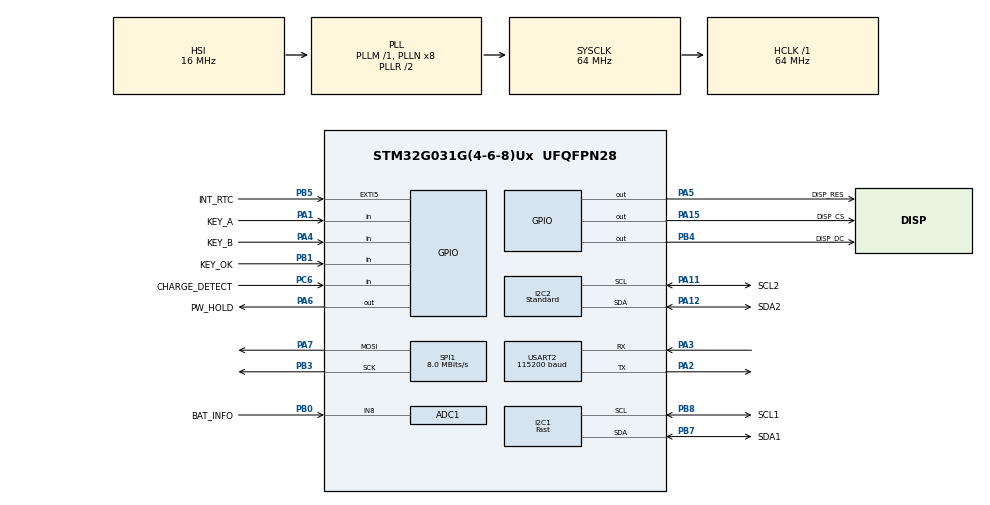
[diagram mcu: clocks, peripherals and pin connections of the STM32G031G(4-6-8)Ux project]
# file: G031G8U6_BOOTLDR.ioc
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ADC1.Channel-1\#ChannelRegularConversion=ADC_CHANNEL_8
ADC1.ClockPrescaler=ADC_CLOCK_SYNC_PCLK_DIV2
ADC1.ContinuousConvMode=ENABLE
ADC1.DMAContinuousRequests=ENABLE
ADC1.EOCSelection=ADC_EOC_SEQ_CONV
ADC1.NbrOfConversion=1
ADC1.NbrOfConversionFlag=1
ADC1.Overrun=ADC_OVR_DATA_PRESERVED
ADC1.OversamplingMode=ENABLE
ADC1.Rank-1\#ChannelRegularConversion=1
ADC1.Ratio=ADC_OVERSAMPLING_RATIO_256
ADC1.Resolution=ADC_RESOLUTION_12B
ADC1.RightBitShift=ADC_RIGHTBITSHIFT_4
ADC1.SamplingTime-1\#ChannelRegularConversion=ADC_SAMPLINGTIME_COMMON_1
ADC1.SamplingTimeCommon1=ADC_SAMPLETIME_39CYCLES_5
ADC1.SamplingTimeCommon2=ADC_SAMPLETIME_39CYCLES_5
ADC1.SelectedChannel=ADC_CHANNEL_8
ADC1.TriggerFrequencyMode=ADC_TRIGGER_FREQ_LOW
ADC1.master=1
Dma.ADC1.2.Direction=DMA_PERIPH_TO_MEMORY
Dma.ADC1.2.EventEnable=DISABLE
Dma.ADC1.2.Instance=DMA1_Channel3
Dma.ADC1.2.MemDataAlignment=DMA_MDATAALIGN_HALFWORD
Dma.ADC1.2.MemInc=DMA_MINC_ENABLE
Dma.ADC1.2.Mode=DMA_CIRCULAR
Dma.ADC1.2.PeriphDataAlignment=DMA_PDATAALIGN_HALFWORD
Dma.ADC1.2.PeriphInc=DMA_PINC_DISABLE
Dma.ADC1.2.Polarity=HAL_DMAMUX_REQ_GEN_RISING
Dma.ADC1.2.Priority=DMA_PRIORITY_VERY_HIGH
Dma.ADC1.2.RequestNumber=1
Dma.ADC1.2.SignalID=NONE
Dma.ADC1.2.SyncEnable=DISABLE
Dma.ADC1.2.SyncPolarity=HAL_DMAMUX_SYNC_NO_EVENT
Dma.ADC1.2.SyncRequestNumber=1
Dma.ADC1.2.SyncSignalID=NONE
Dma.Request0=USART2_RX
Dma.Request1=USART2_TX
Dma.Request2=ADC1
Dma.USART2_RX.0.Direction=DMA_PERIPH_TO_MEMORY
Dma.USART2_RX.0.EventEnable=DISABLE
Dma.USART2_RX.0.Instance=DMA1_Channel1
Dma.USART2_RX.0.MemDataAlignment=DMA_MDATAALIGN_BYTE
Dma.USART2_RX.0.MemInc=DMA_MINC_ENABLE
Dma.USART2_RX.0.Mode=DMA_NORMAL
Dma.USART2_RX.0.PeriphDataAlignment=DMA_PDATAALIGN_BYTE
Dma.USART2_RX.0.PeriphInc=DMA_PINC_DISABLE
Dma.USART2_RX.0.Polarity=HAL_DMAMUX_REQ_GEN_RISING
Dma.USART2_RX.0.Priority=DMA_PRIORITY_LOW
Dma.USART2_RX.0.RequestNumber=1
Dma.USART2_RX.0.SignalID=NONE
Dma.USART2_RX.0.SyncEnable=DISABLE
Dma.USART2_RX.0.SyncPolarity=HAL_DMAMUX_SYNC_NO_EVENT
Dma.USART2_RX.0.SyncRequestNumber=1
Dma.USART2_RX.0.SyncSignalID=NONE
Dma.USART2_TX.1.Direction=DMA_MEMORY_TO_PERIPH
Dma.USART2_TX.1.EventEnable=DISABLE
Dma.USART2_TX.1.Instance=DMA1_Channel2
Dma.USART2_TX.1.MemDataAlignment=DMA_MDATAALIGN_BYTE
Dma.USART2_TX.1.MemInc=DMA_MINC_ENABLE
Dma.USART2_TX.1.Mode=DMA_NORMAL
Dma.USART2_TX.1.PeriphDataAlignment=DMA_PDATAALIGN_BYTE
Dma.USART2_TX.1.PeriphInc=DMA_PINC_DISABLE
Dma.USART2_TX.1.Polarity=HAL_DMAMUX_REQ_GEN_RISING
Dma.USART2_TX.1.Priority=DMA_PRIORITY_LOW
Dma.USART2_TX.1.RequestNumber=1
Dma.USART2_TX.1.SignalID=NONE
Dma.USART2_TX.1.SyncEnable=DISABLE
Dma.USART2_TX.1.SyncPolarity=HAL_DMAMUX_SYNC_NO_EVENT
Dma.USART2_TX.1.SyncRequestNumber=1
Dma.USART2_TX.1.SyncSignalID=NONE
I2C1.I2C_Speed_Mode=I2C_Fast
I2C1.Timing=0x00602173
I2C2.I2C_Speed_Mode=I2C_Standard
I2C2.Timing=0x10707DBC
Mcu.Family=STM32G0
Mcu.Name=STM32G031G(4-6-8)Ux
Mcu.Package=UFQFPN28
NVIC.ADC1_IRQn=true\:0\:0\:true\:false\:true\:true\:true
NVIC.DMA1_Channel1_IRQn=true\:3\:0\:true\:false\:true\:false\:true
NVIC.DMA1_Channel2_3_IRQn=true\:3\:0\:true\:false\:true\:false\:true
NVIC.EXTI4_15_IRQn=true\:2\:0\:true\:false\:true\:true\:true
NVIC.TIM17_IRQn=true\:3\:0\:true\:false\:true\:false\:true
NVIC.TimeBase=TIM17_IRQn
NVIC.TimeBaseIP=TIM17
NVIC.USART2_IRQn=true\:0\:0\:false\:false\:true\:true\:true
PA1.GPIO_Label=KEY_A
PA1.GPIO_PuPd=GPIO_PULLUP
PA1.Signal=GPIO_Input
PA11\ [PA9].GPIO_Label=SCL2
PA11\ [PA9].Mode=I2C
PA11\ [PA9].Signal=I2C2_SCL
PA12\ [PA10].GPIO_Label=SDA2
PA12\ [PA10].Mode=I2C
PA12\ [PA10].Signal=I2C2_SDA
PA13.Mode=Serial_Wire
PA13.Signal=SYS_SWDIO
PA14-BOOT0.Mode=Serial_Wire
PA14-BOOT0.Signal=SYS_SWCLK
PA15.GPIO_Label=DISP_CS
PA15.Signal=GPIO_Output
PA2.Mode=Asynchronous
PA2.Signal=USART2_TX
PA3.Mode=Asynchronous
PA3.Signal=USART2_RX
PA4.GPIO_Label=KEY_B
PA4.GPIO_PuPd=GPIO_PULLUP
PA4.Signal=GPIO_Input
PA5.GPIO_Label=DISP_RES
PA5.Signal=GPIO_Output
PA6.GPIO_Label=PW_HOLD
PA6.Signal=GPIO_Output
PA7.Mode=TX_Only_Simplex_Unidirect_Master
PA7.Signal=SPI1_MOSI
PB0.GPIO_Label=BAT_INFO
PB0.Mode=IN8
PB0.Signal=ADC1_IN8
PB1.GPIO_Label=KEY_OK
PB1.GPIO_PuPd=GPIO_PULLUP
PB1.Signal=GPIO_Input
PB3.Mode=TX_Only_Simplex_Unidirect_Master
PB3.Signal=SPI1_SCK
PB4.GPIO_Label=DISP_DC
PB4.Signal=GPIO_Output
PB5.GPIO_Label=INT_RTC
PB5.GPIO_ModeDefaultEXTI=GPIO_MODE_IT_FALLING
PB5.GPIO_PuPd=GPIO_PULLUP
PB5.Signal=GPXTI5
PB7.GPIO_Label=SDA1
PB7.Mode=I2C
PB7.Signal=I2C1_SDA
PB8.GPIO_Label=SCL1
PB8.Mode=I2C
PB8.Signal=I2C1_SCL
PC6.GPIO_Label=CHARGE_DETECT
PC6.Signal=GPIO_Input
ProjectManager.HeapSize=0x400
ProjectManager.StackSize=0x400
ProjectManager.TargetToolchain=STM32CubeIDE
RCC.ADCFreq_Value=64000000
RCC.AHBFreq_Value=64000000
RCC.CortexFreq_Value=64000000
RCC.EXTERNAL_CLOCK_VALUE=12288000
RCC.HCLKFreq_Value=64000000
RCC.HSE_VALUE=8000000
RCC.HSI_VALUE=16000000
RCC.LSE_VALUE=32768
RCC.SYSCLKFreq_VALUE=64000000
RCC.SYSCLKSource=RCC_SYSCLKSOURCE_PLLCLK
RCC.VCOOutputFreq_Value=128000000
SPI1.BaudRatePrescaler=SPI_BAUDRATEPRESCALER_8
SPI1.CalculateBaudRate=8.0 MBits/s
SPI1.Direction=SPI_DIRECTION_2LINES
SPI1.Mode=SPI_MODE_MASTER
SPI1.VirtualType=VM_MASTER
USART2.BaudRate=115200
USART2.VirtualMode-Asynchronous=VM_ASYNC
VP_SYS_VS_tim17.Mode=TIM17
board=custom

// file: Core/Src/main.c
/* USER CODE BEGIN Header */
/**
  ******************************************************************************
  * @file           : main.c
  * @brief          : Main program body
  ******************************************************************************
  * @attention
  *
  * <h2><center>&copy; Copyright (c) 2022 STMicroelectronics.
  * All rights reserved.</center></h2>
  *
  * This software component is licensed by ST under BSD 3-Clause license,
  * the "License"; You may not use this file except in compliance with the
  * License. You may obtain a copy of the License at:
  *                        opensource.org/licenses/BSD-3-Clause
  *
  ******************************************************************************
  */
/* USER CODE END Header */
#include "main.h"

/* USER CODE BEGIN Includes */
#include <stdio.h>	//提供c库函数printf重定向到USARTx
#include <string.h>
#include <stdarg.h>
#include "BSP.h"
#include "cppports.h"
/* USER CODE END Includes */

ADC_HandleTypeDef hadc1;
DMA_HandleTypeDef hdma_adc1;

I2C_HandleTypeDef hi2c1;
I2C_HandleTypeDef hi2c2;

SPI_HandleTypeDef hspi1;

UART_HandleTypeDef huart2;
DMA_HandleTypeDef hdma_usart2_rx;
DMA_HandleTypeDef hdma_usart2_tx;

void SystemClock_Config(void);
static void MX_GPIO_Init(void);
static void MX_USART2_UART_Init(void);
static void MX_DMA_Init(void);
static void MX_SPI1_Init(void);
static void MX_I2C2_Init(void);
static void MX_I2C1_Init(void);
static void MX_ADC1_Init(void);

int main(void)
{

  /* MCU Configuration--------------------------------------------------------*/

  /* Reset of all peripherals, Initializes the Flash interface and the Systick. */
  HAL_Init();

  /* Configure the system clock */
  SystemClock_Config();

  /* Initialize all configured peripherals */
  MX_GPIO_Init();
  MX_USART2_UART_Init();
  MX_DMA_Init();
  MX_SPI1_Init();
  MX_I2C2_Init();
  MX_I2C1_Init();
  MX_ADC1_Init();
  /* USER CODE BEGIN 2 */
  FRToI2CxSInit();//解锁I2C

  setup();
  /* USER CODE END 2 */

  /* Infinite loop */
  while (1)
  {

  }
}

void SystemClock_Config(void)
{
  RCC_OscInitTypeDef RCC_OscInitStruct = {0};
  RCC_ClkInitTypeDef RCC_ClkInitStruct = {0};
  RCC_PeriphCLKInitTypeDef PeriphClkInit = {0};

  /** Configure the main internal regulator output voltage
  */
  HAL_PWREx_ControlVoltageScaling(PWR_REGULATOR_VOLTAGE_SCALE1);
  /** Initializes the RCC Oscillators according to the specified parameters
  * in the RCC_OscInitTypeDef structure.
  */
  RCC_OscInitStruct.OscillatorType = RCC_OSCILLATORTYPE_HSI;
  RCC_OscInitStruct.HSIState = RCC_HSI_ON;
  RCC_OscInitStruct.HSIDiv = RCC_HSI_DIV1;
  RCC_OscInitStruct.HSICalibrationValue = RCC_HSICALIBRATION_DEFAULT;
  RCC_OscInitStruct.PLL.PLLState = RCC_PLL_ON;
  RCC_OscInitStruct.PLL.PLLSource = RCC_PLLSOURCE_HSI;
  RCC_OscInitStruct.PLL.PLLM = RCC_PLLM_DIV1;
  RCC_OscInitStruct.PLL.PLLN = 8;
  RCC_OscInitStruct.PLL.PLLP = RCC_PLLP_DIV2;
  RCC_OscInitStruct.PLL.PLLQ = RCC_PLLQ_DIV2;
  RCC_OscInitStruct.PLL.PLLR = RCC_PLLR_DIV2;
  if (HAL_RCC_OscConfig(&RCC_OscInitStruct) != HAL_OK)
  {
    Error_Handler();
  }
  /** Initializes the CPU, AHB and APB buses clocks
  */
  RCC_ClkInitStruct.ClockType = RCC_CLOCKTYPE_HCLK|RCC_CLOCKTYPE_SYSCLK
                              |RCC_CLOCKTYPE_PCLK1;
  RCC_ClkInitStruct.SYSCLKSource = RCC_SYSCLKSOURCE_PLLCLK;
  RCC_ClkInitStruct.AHBCLKDivider = RCC_SYSCLK_DIV1;
  RCC_ClkInitStruct.APB1CLKDivider = RCC_HCLK_DIV1;

  if (HAL_RCC_ClockConfig(&RCC_ClkInitStruct, FLASH_LATENCY_2) != HAL_OK)
  {
    Error_Handler();
  }
  /** Initializes the peripherals clocks
  */
  PeriphClkInit.PeriphClockSelection = RCC_PERIPHCLK_I2C1|RCC_PERIPHCLK_ADC;
  PeriphClkInit.I2c1ClockSelection = RCC_I2C1CLKSOURCE_PCLK1;
  PeriphClkInit.AdcClockSelection = RCC_ADCCLKSOURCE_SYSCLK;
  if (HAL_RCCEx_PeriphCLKConfig(&PeriphClkInit) != HAL_OK)
  {
    Error_Handler();
  }
}

static void MX_ADC1_Init(void)
{

  ADC_ChannelConfTypeDef sConfig = {0};

  /** Configure the global features of the ADC (Clock, Resolution, Data Alignment and number of conversion)
  */
  hadc1.Instance = ADC1;
  hadc1.Init.ClockPrescaler = ADC_CLOCK_SYNC_PCLK_DIV2;
  hadc1.Init.Resolution = ADC_RESOLUTION_12B;
  hadc1.Init.DataAlign = ADC_DATAALIGN_RIGHT;
  hadc1.Init.ScanConvMode = ADC_SCAN_DISABLE;
  hadc1.Init.EOCSelection = ADC_EOC_SEQ_CONV;
  hadc1.Init.LowPowerAutoWait = DISABLE;
  hadc1.Init.LowPowerAutoPowerOff = DISABLE;
  hadc1.Init.ContinuousConvMode = ENABLE;
  hadc1.Init.NbrOfConversion = 1;
  hadc1.Init.DiscontinuousConvMode = DISABLE;
  hadc1.Init.ExternalTrigConv = ADC_SOFTWARE_START;
  hadc1.Init.ExternalTrigConvEdge = ADC_EXTERNALTRIGCONVEDGE_NONE;
  hadc1.Init.DMAContinuousRequests = ENABLE;
  hadc1.Init.Overrun = ADC_OVR_DATA_PRESERVED;
  hadc1.Init.SamplingTimeCommon1 = ADC_SAMPLETIME_39CYCLES_5;
  hadc1.Init.SamplingTimeCommon2 = ADC_SAMPLETIME_39CYCLES_5;
  hadc1.Init.OversamplingMode = ENABLE;
  hadc1.Init.Oversampling.Ratio = ADC_OVERSAMPLING_RATIO_256;
  hadc1.Init.Oversampling.RightBitShift = ADC_RIGHTBITSHIFT_4;
  hadc1.Init.Oversampling.TriggeredMode = ADC_TRIGGEREDMODE_SINGLE_TRIGGER;
  hadc1.Init.TriggerFrequencyMode = ADC_TRIGGER_FREQ_LOW;
  if (HAL_ADC_Init(&hadc1) != HAL_OK)
  {
    Error_Handler();
  }
  /** Configure Regular Channel
  */
  sConfig.Channel = ADC_CHANNEL_8;
  sConfig.Rank = ADC_REGULAR_RANK_1;
  sConfig.SamplingTime = ADC_SAMPLINGTIME_COMMON_1;
  if (HAL_ADC_ConfigChannel(&hadc1, &sConfig) != HAL_OK)
  {
    Error_Handler();
  }

}

static void MX_I2C1_Init(void)
{

  hi2c1.Instance = I2C1;
  hi2c1.Init.Timing = 0x00602173;
  hi2c1.Init.OwnAddress1 = 0;
  hi2c1.Init.AddressingMode = I2C_ADDRESSINGMODE_7BIT;
  hi2c1.Init.DualAddressMode = I2C_DUALADDRESS_DISABLE;
  hi2c1.Init.OwnAddress2 = 0;
  hi2c1.Init.OwnAddress2Masks = I2C_OA2_NOMASK;
  hi2c1.Init.GeneralCallMode = I2C_GENERALCALL_DISABLE;
  hi2c1.Init.NoStretchMode = I2C_NOSTRETCH_DISABLE;
  if (HAL_I2C_Init(&hi2c1) != HAL_OK)
  {
    Error_Handler();
  }
  /** Configure Analogue filter
  */
  if (HAL_I2CEx_ConfigAnalogFilter(&hi2c1, I2C_ANALOGFILTER_ENABLE) != HAL_OK)
  {
    Error_Handler();
  }
  /** Configure Digital filter
  */
  if (HAL_I2CEx_ConfigDigitalFilter(&hi2c1, 0) != HAL_OK)
  {
    Error_Handler();
  }

}

static void MX_I2C2_Init(void)
{

  hi2c2.Instance = I2C2;
  hi2c2.Init.Timing = 0x10707DBC;
  hi2c2.Init.OwnAddress1 = 0;
  hi2c2.Init.AddressingMode = I2C_ADDRESSINGMODE_7BIT;
  hi2c2.Init.DualAddressMode = I2C_DUALADDRESS_DISABLE;
  hi2c2.Init.OwnAddress2 = 0;
  hi2c2.Init.OwnAddress2Masks = I2C_OA2_NOMASK;
  hi2c2.Init.GeneralCallMode = I2C_GENERALCALL_DISABLE;
  hi2c2.Init.NoStretchMode = I2C_NOSTRETCH_DISABLE;
  if (HAL_I2C_Init(&hi2c2) != HAL_OK)
  {
    Error_Handler();
  }
  /** Configure Analogue filter
  */
  if (HAL_I2CEx_ConfigAnalogFilter(&hi2c2, I2C_ANALOGFILTER_ENABLE) != HAL_OK)
  {
    Error_Handler();
  }
  /** Configure Digital filter
  */
  if (HAL_I2CEx_ConfigDigitalFilter(&hi2c2, 0) != HAL_OK)
  {
    Error_Handler();
  }

}

static void MX_SPI1_Init(void)
{

  /* SPI1 parameter configuration*/
  hspi1.Instance = SPI1;
  hspi1.Init.Mode = SPI_MODE_MASTER;
  hspi1.Init.Direction = SPI_DIRECTION_2LINES;
  hspi1.Init.DataSize = SPI_DATASIZE_8BIT;
  hspi1.Init.CLKPolarity = SPI_POLARITY_LOW;
  hspi1.Init.CLKPhase = SPI_PHASE_1EDGE;
  hspi1.Init.NSS = SPI_NSS_SOFT;
  hspi1.Init.BaudRatePrescaler = SPI_BAUDRATEPRESCALER_8;
  hspi1.Init.FirstBit = SPI_FIRSTBIT_MSB;
  hspi1.Init.TIMode = SPI_TIMODE_DISABLE;
  hspi1.Init.CRCCalculation = SPI_CRCCALCULATION_DISABLE;
  hspi1.Init.CRCPolynomial = 7;
  hspi1.Init.CRCLength = SPI_CRC_LENGTH_DATASIZE;
  hspi1.Init.NSSPMode = SPI_NSS_PULSE_ENABLE;
  if (HAL_SPI_Init(&hspi1) != HAL_OK)
  {
    Error_Handler();
  }

}

static void MX_USART2_UART_Init(void)
{

  huart2.Instance = USART2;
  huart2.Init.BaudRate = 115200;
  huart2.Init.WordLength = UART_WORDLENGTH_8B;
  huart2.Init.StopBits = UART_STOPBITS_1;
  huart2.Init.Parity = UART_PARITY_NONE;
  huart2.Init.Mode = UART_MODE_TX_RX;
  huart2.Init.HwFlowCtl = UART_HWCONTROL_NONE;
  huart2.Init.OverSampling = UART_OVERSAMPLING_16;
  huart2.Init.OneBitSampling = UART_ONE_BIT_SAMPLE_DISABLE;
  huart2.Init.ClockPrescaler = UART_PRESCALER_DIV1;
  huart2.AdvancedInit.AdvFeatureInit = UART_ADVFEATURE_NO_INIT;
  if (HAL_UART_Init(&huart2) != HAL_OK)
  {
    Error_Handler();
  }

}

static void MX_DMA_Init(void)
{

  /* DMA controller clock enable */
  __HAL_RCC_DMA1_CLK_ENABLE();

  /* DMA interrupt init */
  /* DMA1_Channel1_IRQn interrupt configuration */
  HAL_NVIC_SetPriority(DMA1_Channel1_IRQn, 3, 0);
  HAL_NVIC_EnableIRQ(DMA1_Channel1_IRQn);
  /* DMA1_Channel2_3_IRQn interrupt configuration */
  HAL_NVIC_SetPriority(DMA1_Channel2_3_IRQn, 3, 0);
  HAL_NVIC_EnableIRQ(DMA1_Channel2_3_IRQn);

}

static void MX_GPIO_Init(void)
{
  GPIO_InitTypeDef GPIO_InitStruct = {0};

  /* GPIO Ports Clock Enable */
  __HAL_RCC_GPIOA_CLK_ENABLE();
  __HAL_RCC_GPIOB_CLK_ENABLE();
  __HAL_RCC_GPIOC_CLK_ENABLE();

  /*Configure GPIO pin Output Level */
  HAL_GPIO_WritePin(GPIOA, DISP_RES_Pin|PW_HOLD_Pin|DISP_CS_Pin, GPIO_PIN_RESET);

  /*Configure GPIO pin Output Level */
  HAL_GPIO_WritePin(DISP_DC_GPIO_Port, DISP_DC_Pin, GPIO_PIN_RESET);

  /*Configure GPIO pins : KEY_A_Pin KEY_B_Pin */
  GPIO_InitStruct.Pin = KEY_A_Pin|KEY_B_Pin;
  GPIO_InitStruct.Mode = GPIO_MODE_INPUT;
  GPIO_InitStruct.Pull = GPIO_PULLUP;
  HAL_GPIO_Init(GPIOA, &GPIO_InitStruct);

  /*Configure GPIO pins : DISP_RES_Pin PW_HOLD_Pin DISP_CS_Pin */
  GPIO_InitStruct.Pin = DISP_RES_Pin|PW_HOLD_Pin|DISP_CS_Pin;
  GPIO_InitStruct.Mode = GPIO_MODE_OUTPUT_PP;
  GPIO_InitStruct.Pull = GPIO_NOPULL;
  GPIO_InitStruct.Speed = GPIO_SPEED_FREQ_LOW;
  HAL_GPIO_Init(GPIOA, &GPIO_InitStruct);

  /*Configure GPIO pin : KEY_OK_Pin */
  GPIO_InitStruct.Pin = KEY_OK_Pin;
  GPIO_InitStruct.Mode = GPIO_MODE_INPUT;
  GPIO_InitStruct.Pull = GPIO_PULLUP;
  HAL_GPIO_Init(KEY_OK_GPIO_Port, &GPIO_InitStruct);

  /*Configure GPIO pin : CHARGE_DETECT_Pin */
  GPIO_InitStruct.Pin = CHARGE_DETECT_Pin;
  GPIO_InitStruct.Mode = GPIO_MODE_INPUT;
  GPIO_InitStruct.Pull = GPIO_NOPULL;
  HAL_GPIO_Init(CHARGE_DETECT_GPIO_Port, &GPIO_InitStruct);

  /*Configure GPIO pin : DISP_DC_Pin */
  GPIO_InitStruct.Pin = DISP_DC_Pin;
  GPIO_InitStruct.Mode = GPIO_MODE_OUTPUT_PP;
  GPIO_InitStruct.Pull = GPIO_NOPULL;
  GPIO_InitStruct.Speed = GPIO_SPEED_FREQ_LOW;
  HAL_GPIO_Init(DISP_DC_GPIO_Port, &GPIO_InitStruct);

  /*Configure GPIO pin : INT_RTC_Pin */
  GPIO_InitStruct.Pin = INT_RTC_Pin;
  GPIO_InitStruct.Mode = GPIO_MODE_IT_FALLING;
  GPIO_InitStruct.Pull = GPIO_PULLUP;
  HAL_GPIO_Init(INT_RTC_GPIO_Port, &GPIO_InitStruct);

  /* EXTI interrupt init*/
  HAL_NVIC_SetPriority(EXTI4_15_IRQn, 2, 0);
  HAL_NVIC_EnableIRQ(EXTI4_15_IRQn);

}

/* USER CODE BEGIN 4 */
void EXT_I2C1_Init(){
	MX_I2C1_Init();
}
/* USER CODE END 4 */

void HAL_TIM_PeriodElapsedCallback(TIM_HandleTypeDef *htim)
{
  if (htim->Instance == TIM17) {
    HAL_IncTick();
  }
}

void Error_Handler(void)
{
  __disable_irq();
  while (1)
  {
  }
}

/************************ (C) COPYRIGHT STMicroelectronics *****END OF FILE****/
